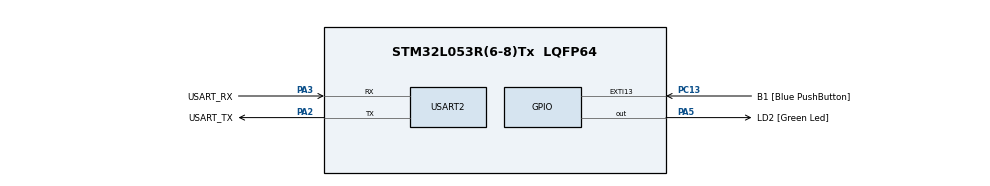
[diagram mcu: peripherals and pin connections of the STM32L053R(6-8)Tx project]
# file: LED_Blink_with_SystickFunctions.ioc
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Mcu.Family=STM32L0
Mcu.Name=STM32L053R(6-8)Tx
Mcu.Package=LQFP64
PA13.GPIO_Label=TMS
PA13.Mode=Serial_Wire
PA13.Signal=SYS_SWDIO
PA14.GPIO_Label=TCK
PA14.Mode=Serial_Wire
PA14.Signal=SYS_SWCLK
PA2.GPIO_Label=USART_TX
PA2.Mode=Asynchronous
PA2.Signal=USART2_TX
PA3.GPIO_Label=USART_RX
PA3.Mode=Asynchronous
PA3.Signal=USART2_RX
PA5.GPIO_Label=LD2 [Green Led]
PA5.Signal=GPIO_Output
PC13.GPIO_Label=B1 [Blue PushButton]
PC13.GPIO_ModeDefaultEXTI=GPIO_MODE_IT_FALLING
PC13.Signal=GPXTI13
PC14-OSC32_IN.Mode=LSE-External-Oscillator
PC14-OSC32_IN.Signal=RCC_OSC32_IN
PC15-OSC32_OUT.Mode=LSE-External-Oscillator
PC15-OSC32_OUT.Signal=RCC_OSC32_OUT
PH0-OSC_IN.Mode=HSE-External-Clock-Source
PH0-OSC_IN.Signal=RCC_OSC_IN
PH1-OSC_OUT.Signal=RCC_OSC_OUT
ProjectManager.HeapSize=0x200
ProjectManager.StackSize=0x400
ProjectManager.TargetToolchain=TrueSTUDIO
RCC.AHBFreq_Value=16000000
RCC.APB1Freq_Value=16000000
RCC.APB1TimFreq_Value=16000000
RCC.APB2Freq_Value=16000000
RCC.APB2TimFreq_Value=16000000
RCC.HCLKFreq_Value=16000000
RCC.HSE_VALUE=8000000
RCC.HSI16_VALUE=16000000
RCC.HSI48_VALUE=48000000
RCC.HSI_VALUE=16000000
RCC.MSI_VALUE=2097000
RCC.SYSCLKFreq_VALUE=16000000
RCC.SYSCLKSource=RCC_SYSCLKSOURCE_HSI
RCC.VCOOutputFreq_Value=48000000
USART2.VirtualMode-Asynchronous=VM_ASYNC
board=NUCLEO-L053R8

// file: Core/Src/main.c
/* USER CODE BEGIN Header */
/**
 ******************************************************************************
 * @file           : main.c
 * @brief          : Main program body
 ******************************************************************************
 * @attention
 *
 * Copyright (c) 2022 STMicroelectronics.
 * All rights reserved.
 *
 * This software is licensed under terms that can be found in the LICENSE file
 * in the root directory of this software component.
 * If no LICENSE file comes with this software, it is provided AS-IS.
 *
 ******************************************************************************
 */
/* USER CODE END Header */
#include "main.h"

/* USER CODE BEGIN Includes */

uint16_t usTimeMyTime = 0;

//Created function for next projects so i don't change it by variable but with function.
void setLedToggleTimer(uint16_t usTimeMs) {
	usTimeMyTime = usTimeMs;
}

/* USER CODE END Includes */

void SystemClock_Config(void);
static void MX_GPIO_Init(void);
static void MX_USART2_UART_Init(void);

int main(void) {

	/* MCU Configuration--------------------------------------------------------*/

	/* Reset of all peripherals, Initializes the Flash interface and the Systick. */
	LL_APB2_GRP1_EnableClock(LL_APB2_GRP1_PERIPH_SYSCFG);
	LL_APB1_GRP1_EnableClock(LL_APB1_GRP1_PERIPH_PWR);

	/* Configure the system clock */
	SystemClock_Config();

	/* USER CODE BEGIN SysInit */
	//This function calls systick interrupt for every millisecond.
	SysTick_Config(SystemCoreClock / 1000);

	setLedToggleTimer(2000);

	/* USER CODE END SysInit */

	/* Initialize all configured peripherals */
	MX_GPIO_Init();
	MX_USART2_UART_Init();

	/* Infinite loop */
	while (1) {

	}
}

void SystemClock_Config(void) {
	LL_FLASH_SetLatency(LL_FLASH_LATENCY_0);
	while (LL_FLASH_GetLatency() != LL_FLASH_LATENCY_0) {
	}
	LL_PWR_SetRegulVoltageScaling(LL_PWR_REGU_VOLTAGE_SCALE1);
	LL_RCC_HSI_Enable();

	/* Wait till HSI is ready */
	while (LL_RCC_HSI_IsReady() != 1) {

	}
	LL_RCC_HSI_SetCalibTrimming(16);
	LL_RCC_SetAHBPrescaler(LL_RCC_SYSCLK_DIV_1);
	LL_RCC_SetAPB1Prescaler(LL_RCC_APB1_DIV_1);
	LL_RCC_SetAPB2Prescaler(LL_RCC_APB2_DIV_1);
	LL_RCC_SetSysClkSource(LL_RCC_SYS_CLKSOURCE_HSI);

	/* Wait till System clock is ready */
	while (LL_RCC_GetSysClkSource() != LL_RCC_SYS_CLKSOURCE_STATUS_HSI) {

	}

	LL_Init1msTick(16000000);

	LL_SetSystemCoreClock(16000000);
	LL_RCC_SetUSARTClockSource(LL_RCC_USART2_CLKSOURCE_PCLK1);
}

static void MX_USART2_UART_Init(void) {

	LL_USART_InitTypeDef USART_InitStruct = { 0 };

	LL_GPIO_InitTypeDef GPIO_InitStruct = { 0 };

	/* Peripheral clock enable */
	LL_APB1_GRP1_EnableClock(LL_APB1_GRP1_PERIPH_USART2);

	LL_IOP_GRP1_EnableClock(LL_IOP_GRP1_PERIPH_GPIOA);
	/**USART2 GPIO Configuration
	 PA2   ------> USART2_TX
	 PA3   ------> USART2_RX
	 */
	GPIO_InitStruct.Pin = LL_GPIO_PIN_2;
	GPIO_InitStruct.Mode = LL_GPIO_MODE_ALTERNATE;
	GPIO_InitStruct.Speed = LL_GPIO_SPEED_FREQ_VERY_HIGH;
	GPIO_InitStruct.OutputType = LL_GPIO_OUTPUT_PUSHPULL;
	GPIO_InitStruct.Pull = LL_GPIO_PULL_NO;
	GPIO_InitStruct.Alternate = LL_GPIO_AF_4;
	LL_GPIO_Init(GPIOA, &GPIO_InitStruct);

	GPIO_InitStruct.Pin = LL_GPIO_PIN_3;
	GPIO_InitStruct.Mode = LL_GPIO_MODE_ALTERNATE;
	GPIO_InitStruct.Speed = LL_GPIO_SPEED_FREQ_VERY_HIGH;
	GPIO_InitStruct.OutputType = LL_GPIO_OUTPUT_PUSHPULL;
	GPIO_InitStruct.Pull = LL_GPIO_PULL_NO;
	GPIO_InitStruct.Alternate = LL_GPIO_AF_4;
	LL_GPIO_Init(GPIOA, &GPIO_InitStruct);

	USART_InitStruct.BaudRate = 115200;
	USART_InitStruct.DataWidth = LL_USART_DATAWIDTH_8B;
	USART_InitStruct.StopBits = LL_USART_STOPBITS_1;
	USART_InitStruct.Parity = LL_USART_PARITY_NONE;
	USART_InitStruct.TransferDirection = LL_USART_DIRECTION_TX_RX;
	USART_InitStruct.HardwareFlowControl = LL_USART_HWCONTROL_NONE;
	USART_InitStruct.OverSampling = LL_USART_OVERSAMPLING_16;
	LL_USART_Init(USART2, &USART_InitStruct);
	LL_USART_ConfigAsyncMode(USART2);
	LL_USART_Enable(USART2);

}

static void MX_GPIO_Init(void) {
	LL_EXTI_InitTypeDef EXTI_InitStruct = { 0 };
	LL_GPIO_InitTypeDef GPIO_InitStruct = { 0 };

	/* GPIO Ports Clock Enable */
	LL_IOP_GRP1_EnableClock(LL_IOP_GRP1_PERIPH_GPIOC);
	LL_IOP_GRP1_EnableClock(LL_IOP_GRP1_PERIPH_GPIOH);
	LL_IOP_GRP1_EnableClock(LL_IOP_GRP1_PERIPH_GPIOA);

	/**/
	LL_GPIO_ResetOutputPin(GPIOA, LL_GPIO_PIN_5);

	/**/
	LL_SYSCFG_SetEXTISource(LL_SYSCFG_EXTI_PORTC, LL_SYSCFG_EXTI_LINE13);

	/**/
	LL_GPIO_SetPinPull(GPIOC, LL_GPIO_PIN_13, LL_GPIO_PULL_NO);

	/**/
	LL_GPIO_SetPinMode(GPIOC, LL_GPIO_PIN_13, LL_GPIO_MODE_INPUT);

	/**/
	EXTI_InitStruct.Line_0_31 = LL_EXTI_LINE_13;
	EXTI_InitStruct.LineCommand = ENABLE;
	EXTI_InitStruct.Mode = LL_EXTI_MODE_IT;
	EXTI_InitStruct.Trigger = LL_EXTI_TRIGGER_FALLING;
	LL_EXTI_Init(&EXTI_InitStruct);

	/**/
	GPIO_InitStruct.Pin = LL_GPIO_PIN_5;
	GPIO_InitStruct.Mode = LL_GPIO_MODE_OUTPUT;
	GPIO_InitStruct.Speed = LL_GPIO_SPEED_FREQ_LOW;
	GPIO_InitStruct.OutputType = LL_GPIO_OUTPUT_PUSHPULL;
	GPIO_InitStruct.Pull = LL_GPIO_PULL_NO;
	LL_GPIO_Init(GPIOA, &GPIO_InitStruct);

}

void Error_Handler(void) {
	__disable_irq();
	while (1) {
	}
}
